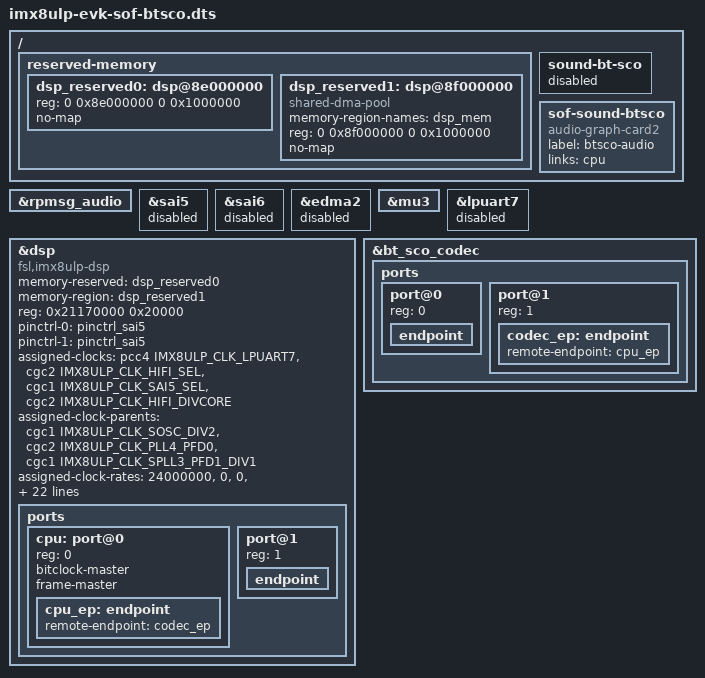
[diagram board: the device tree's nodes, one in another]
// SPDX-License-Identifier: (GPL-2.0+ OR MIT)
/*
 * Copyright 2021 NXP
 */

#include "imx8ulp-evk.dts"

/delete-node/ &dsp_reserved;
/delete-node/ &dsp_reserved_heap;
/delete-node/ &dsp_vdev0vring0;
/delete-node/ &dsp_vdev0vring1;
/delete-node/ &dsp_vdev0buffer;

/ {
	reserved-memory {
		dsp_reserved0: dsp@8e000000 {
			reg = <0 0x8e000000 0 0x1000000>;
			no-map;
		};
		dsp_reserved1: dsp@8f000000 {
			compatible = "shared-dma-pool";
			memory-region-names = "dsp_mem";
			reg = <0 0x8f000000 0 0x1000000>;
			no-map;
		};
	};

	sound-bt-sco {
		status = "disabled";
	};

	sof-sound-btsco {
		compatible = "audio-graph-card2";
		label = "btsco-audio";
		links = <&cpu>;
	};
};

&rpmsg_audio {
	status = "okay";
};

&sai5 {
	status = "disabled";
};

&sai6 {
	status = "disabled";
};

&edma2 {
	status = "disabled";
};

&mu3 {
	status = "okay";
};

&lpuart7 {
	status = "disabled";
};

&dsp {
	compatible = "fsl,imx8ulp-dsp";
	memory-reserved = <&dsp_reserved0>;
	memory-region = <&dsp_reserved1>;
	reg = <0x21170000 0x20000>;
	pinctrl-names = "default", "sleep";
	pinctrl-0 = <&pinctrl_sai5>;
	pinctrl-1 = <&pinctrl_sai5>;

	assigned-clocks = <&pcc4 IMX8ULP_CLK_LPUART7>, <&cgc2 IMX8ULP_CLK_HIFI_SEL>, <&cgc1 IMX8ULP_CLK_SAI5_SEL>, <&cgc2 IMX8ULP_CLK_HIFI_DIVCORE>;
	assigned-clock-parents = <&cgc1 IMX8ULP_CLK_SOSC_DIV2>, <&cgc2 IMX8ULP_CLK_PLL4_PFD0>,  <&cgc1 IMX8ULP_CLK_SPLL3_PFD1_DIV1>;
	assigned-clock-rates = <24000000>, <0>, <0>, <475200000>;

	clocks = <&cgc2 IMX8ULP_CLK_HIFI_DIVCORE>,
			<&cgc2 IMX8ULP_CLK_LPAV_BUS_DIV>,
			<&cgc2 IMX8ULP_CLK_HIFI_DIVPLAT>,
			<&pcc5 IMX8ULP_CLK_MU3_B>,
			<&pcc4 IMX8ULP_CLK_SAI5>, <&cgc1 IMX8ULP_CLK_DUMMY>,
			<&cgc1 IMX8ULP_CLK_SAI5_SEL>,
			<&pcc5 IMX8ULP_CLK_DMA2_MP>,
			<&pcc5 IMX8ULP_CLK_DMA2_CH0>, <&pcc5 IMX8ULP_CLK_DMA2_CH1>,
			<&pcc5 IMX8ULP_CLK_DMA2_CH2>, <&pcc5 IMX8ULP_CLK_DMA2_CH3>,
			<&pcc5 IMX8ULP_CLK_DMA2_CH4>, <&pcc5 IMX8ULP_CLK_DMA2_CH5>,
			<&pcc5 IMX8ULP_CLK_DMA2_CH6>, <&pcc5 IMX8ULP_CLK_DMA2_CH7>,
			<&pcc4 IMX8ULP_CLK_LPUART7>;
	clock-names = "core", "ipg", "ocram", "mu",
				"bus", "mclk0", "mclk1",
				"edma-mp-clk",
						"edma2-chan0-clk", "edma2-chan1-clk",
						"edma2-chan2-clk", "edma2-chan3-clk",
						"edma2-chan4-clk", "edma2-chan5-clk",
						"edma2-chan6-clk", "edma2-chan7-clk",
						"lpuart7";

	mbox-names = "txdb0", "txdb1", "rxdb0", "rxdb1";
	mboxes = <&mu3 2 0>,
			<&mu3 2 1>,
			<&mu3 3 0>,
			<&mu3 3 1>;
	/delete-property/ firmware-name;
	tplg-name = "sof-imx8ulp-btsco.tplg";
	machine-drv-name = "asoc-audio-graph-card2";


	status = "okay";

	ports {
		#address-cells = <1>;
		#size-cells = <0>;

		cpu: port@0 {
			reg = <0>;
			bitclock-master;
			frame-master;

			cpu_ep: endpoint { remote-endpoint = <&codec_ep>; };
		};
		port@1 { reg = <1>; endpoint { /* not used */ }; };
       };
};

&bt_sco_codec {
	status = "okay";

	ports {
		#address-cells = <1>;
		#size-cells = <0>;

		port@0 { reg = <0>; endpoint { /* not used */ }; };
		port@1 {
			reg = <1>;
			codec_ep: endpoint { remote-endpoint = <&cpu_ep>; };
		};
       };
};
